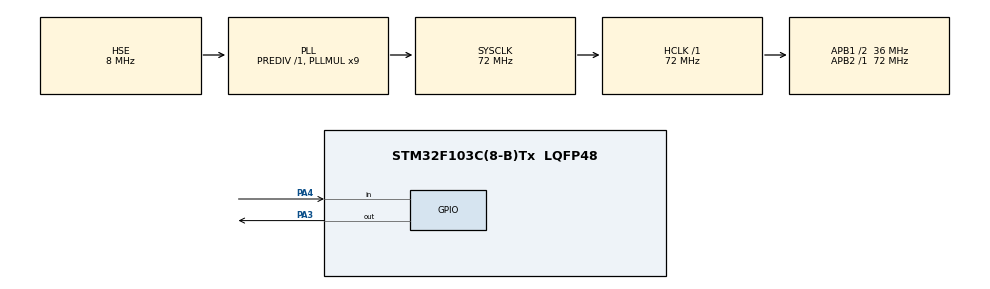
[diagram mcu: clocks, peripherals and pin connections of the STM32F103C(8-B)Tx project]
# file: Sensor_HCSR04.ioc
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Mcu.Family=STM32F1
RCC.PLLSourceVirtual=RCC_PLLSOURCE_HSE
PD1-OSC_OUT.Mode=HSE-External-Oscillator
PD0-OSC_IN.Signal=RCC_OSC_IN
RCC.APB1CLKDivider=RCC_HCLK_DIV2
RCC.SYSCLKSource=RCC_SYSCLKSOURCE_PLLCLK
ProjectManager.StackSize=0x400
PD1-OSC_OUT.Signal=RCC_OSC_OUT
PA13.Signal=SYS_JTMS-SWDIO
TIM1.Prescaler=71
ProjectManager.TargetToolchain=STM32CubeIDE
RCC.HCLKFreq_Value=72000000
RCC.APB2TimFreq_Value=72000000
RCC.USBFreq_Value=72000000
RCC.AHBFreq_Value=72000000
PD0-OSC_IN.Mode=HSE-External-Oscillator
board=custom
RCC.PLLMUL=RCC_PLL_MUL9
RCC.APB2Freq_Value=72000000
PA14.Mode=Serial_Wire
PA13.Mode=Serial_Wire
Mcu.Name=STM32F103C(8-B)Tx
VP_TIM1_VS_ClockSourceINT.Mode=Internal
PA4.Signal=GPIO_Input
RCC.SYSCLKFreq_VALUE=72000000
Mcu.Package=LQFP48
PA14.Signal=SYS_JTCK-SWCLK
ProjectManager.HeapSize=0x200
NVIC.PriorityGroup=NVIC_PRIORITYGROUP_4
RCC.APB1TimFreq_Value=72000000
RCC.APB1Freq_Value=36000000
PA3.Signal=GPIO_Output

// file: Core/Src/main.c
/* USER CODE BEGIN Header */
/**
 * https://microcontrollerslab.com/hc-sr04-ultrasonic-sensor-stm32-blue-pill-stm32cubeide/
 * https://community.st.com/t5/stm32-mcus/how-to-use-the-stm32cubeide-terminal-to-send-and-receive-data/ta-p/49434
 * https://community.st.com/t5/stm32-mcus/how-to-redirect-the-printf-function-to-a-uart-for-debug-messages/ta-p/49865
 * https://community.st.com/t5/stm32cubeide-mcus/stm32cubeide-how-to-use-real-time-variables/td-p/242486
  ******************************************************************************
  * @file           : main.c
  * @brief          : Main program body
  ******************************************************************************
  * @attention
  *
  * <h2><center>&copy; Copyright (c) 2024 STMicroelectronics.
  * All rights reserved.</center></h2>
  *
  * This software component is licensed by ST under BSD 3-Clause license,
  * the "License"; You may not use this file except in compliance with the
  * License. You may obtain a copy of the License at:
  *                        opensource.org/licenses/BSD-3-Clause
  *
  ******************************************************************************
  */
/* USER CODE END Header */
#include "main.h"

TIM_HandleTypeDef htim1;

/* USER CODE BEGIN PV */
#define TRIG_PIN GPIO_PIN_3
#define TRIG_PORT GPIOA
#define ECHO_PIN GPIO_PIN_4
#define ECHO_PORT GPIOA

uint32_t pMillis;
uint32_t val1 = 0;
uint32_t val2 = 0;
uint16_t distance  = 0;
char string[15];

/* USER CODE END PV */

void SystemClock_Config(void);
static void MX_GPIO_Init(void);
static void MX_TIM1_Init(void);

int main(void)
{

  /* MCU Configuration--------------------------------------------------------*/

  /* Reset of all peripherals, Initializes the Flash interface and the Systick. */
  HAL_Init();

  /* Configure the system clock */
  SystemClock_Config();

  /* Initialize all configured peripherals */
  MX_GPIO_Init();
  MX_TIM1_Init();
  /* USER CODE BEGIN 2 */
  HAL_TIM_Base_Start(&htim1);
  HAL_GPIO_WritePin(TRIG_PORT, TRIG_PIN, GPIO_PIN_RESET);
  /* USER CODE END 2 */

  /* Infinite loop */
  while (1)
  {
	  HAL_GPIO_WritePin(TRIG_PORT, TRIG_PIN, GPIO_PIN_SET);
	  __HAL_TIM_SET_COUNTER(&htim1, 0);
	   while (__HAL_TIM_GET_COUNTER (&htim1) < 10);  // wait for 10 us
	   HAL_GPIO_WritePin(TRIG_PORT, TRIG_PIN, GPIO_PIN_RESET);

	   pMillis = HAL_GetTick();
	   while (!(HAL_GPIO_ReadPin (ECHO_PORT, ECHO_PIN)) && pMillis + 10 >  HAL_GetTick());
	   val1 = __HAL_TIM_GET_COUNTER (&htim1);

	   pMillis = HAL_GetTick();
	   while ((HAL_GPIO_ReadPin (ECHO_PORT, ECHO_PIN)) && pMillis + 50 > HAL_GetTick());
	   val2 = __HAL_TIM_GET_COUNTER (&htim1);

	   distance = (val2-val1)* 0.034/2;
	   sprintf(string,"%d    ", distance);
	  // printf("Hello World\n\r");
	   HAL_Delay(50);
  }
}

void SystemClock_Config(void)
{
  RCC_OscInitTypeDef RCC_OscInitStruct = {0};
  RCC_ClkInitTypeDef RCC_ClkInitStruct = {0};

  /** Initializes the RCC Oscillators according to the specified parameters
  * in the RCC_OscInitTypeDef structure.
  */
  RCC_OscInitStruct.OscillatorType = RCC_OSCILLATORTYPE_HSE;
  RCC_OscInitStruct.HSEState = RCC_HSE_ON;
  RCC_OscInitStruct.HSEPredivValue = RCC_HSE_PREDIV_DIV1;
  RCC_OscInitStruct.HSIState = RCC_HSI_ON;
  RCC_OscInitStruct.PLL.PLLState = RCC_PLL_ON;
  RCC_OscInitStruct.PLL.PLLSource = RCC_PLLSOURCE_HSE;
  RCC_OscInitStruct.PLL.PLLMUL = RCC_PLL_MUL9;
  if (HAL_RCC_OscConfig(&RCC_OscInitStruct) != HAL_OK)
  {
    Error_Handler();
  }
  /** Initializes the CPU, AHB and APB buses clocks
  */
  RCC_ClkInitStruct.ClockType = RCC_CLOCKTYPE_HCLK|RCC_CLOCKTYPE_SYSCLK
                              |RCC_CLOCKTYPE_PCLK1|RCC_CLOCKTYPE_PCLK2;
  RCC_ClkInitStruct.SYSCLKSource = RCC_SYSCLKSOURCE_PLLCLK;
  RCC_ClkInitStruct.AHBCLKDivider = RCC_SYSCLK_DIV1;
  RCC_ClkInitStruct.APB1CLKDivider = RCC_HCLK_DIV2;
  RCC_ClkInitStruct.APB2CLKDivider = RCC_HCLK_DIV1;

  if (HAL_RCC_ClockConfig(&RCC_ClkInitStruct, FLASH_LATENCY_2) != HAL_OK)
  {
    Error_Handler();
  }
}

static void MX_TIM1_Init(void)
{

  TIM_ClockConfigTypeDef sClockSourceConfig = {0};
  TIM_MasterConfigTypeDef sMasterConfig = {0};

  htim1.Instance = TIM1;
  htim1.Init.Prescaler = 71;
  htim1.Init.CounterMode = TIM_COUNTERMODE_UP;
  htim1.Init.Period = 65535;
  htim1.Init.ClockDivision = TIM_CLOCKDIVISION_DIV1;
  htim1.Init.RepetitionCounter = 0;
  htim1.Init.AutoReloadPreload = TIM_AUTORELOAD_PRELOAD_DISABLE;
  if (HAL_TIM_Base_Init(&htim1) != HAL_OK)
  {
    Error_Handler();
  }
  sClockSourceConfig.ClockSource = TIM_CLOCKSOURCE_INTERNAL;
  if (HAL_TIM_ConfigClockSource(&htim1, &sClockSourceConfig) != HAL_OK)
  {
    Error_Handler();
  }
  sMasterConfig.MasterOutputTrigger = TIM_TRGO_RESET;
  sMasterConfig.MasterSlaveMode = TIM_MASTERSLAVEMODE_DISABLE;
  if (HAL_TIMEx_MasterConfigSynchronization(&htim1, &sMasterConfig) != HAL_OK)
  {
    Error_Handler();
  }

}

static void MX_GPIO_Init(void)
{
  GPIO_InitTypeDef GPIO_InitStruct = {0};

  /* GPIO Ports Clock Enable */
  __HAL_RCC_GPIOD_CLK_ENABLE();
  __HAL_RCC_GPIOA_CLK_ENABLE();

  /*Configure GPIO pin Output Level */
  HAL_GPIO_WritePin(GPIOA, GPIO_PIN_3, GPIO_PIN_RESET);

  /*Configure GPIO pin : PA3 */
  GPIO_InitStruct.Pin = GPIO_PIN_3;
  GPIO_InitStruct.Mode = GPIO_MODE_OUTPUT_PP;
  GPIO_InitStruct.Pull = GPIO_NOPULL;
  GPIO_InitStruct.Speed = GPIO_SPEED_FREQ_LOW;
  HAL_GPIO_Init(GPIOA, &GPIO_InitStruct);

  /*Configure GPIO pin : PA4 */
  GPIO_InitStruct.Pin = GPIO_PIN_4;
  GPIO_InitStruct.Mode = GPIO_MODE_INPUT;
  GPIO_InitStruct.Pull = GPIO_NOPULL;
  HAL_GPIO_Init(GPIOA, &GPIO_InitStruct);

}

void Error_Handler(void)
{
  __disable_irq();
  while (1)
  {
  }
}

/************************ (C) COPYRIGHT STMicroelectronics *****END OF FILE****/
